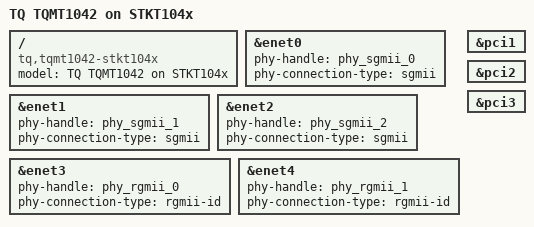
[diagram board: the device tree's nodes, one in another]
// SPDX-License-Identifier: GPL-2.0-or-later
/*
 * TQMT1042 on STKT104x with serdes configuration 0x86 Device Tree Source
 *
 * Copyright (c) 2016-2023 TQ-Systems GmbH <license@tq-group.com>, D-82229 Seefeld, Germany.
 * Copyright 2014 Freescale Semiconductor Inc.
 * Author: Stefan Lange, Max Merchel, Gregor Herburger
 *
 */

#include "t104xsi-pre.dtsi"

#include "tqmt10xx.dtsi"
#include "stkt104x.dtsi"

/ {
	model = "TQ TQMT1042 on STKT104x";
	compatible = "tq,tqmt1042-stkt104x", "tq,tqmt1042";
};

#include "t1042si-post.dtsi"

&enet0 {
	phy-handle = <&phy_sgmii_0>;
	phy-connection-type = "sgmii";
};

&enet1 {
	phy-handle = <&phy_sgmii_1>;
	phy-connection-type = "sgmii";
};

&enet2 {
	phy-handle = <&phy_sgmii_2>;
	phy-connection-type = "sgmii";
};

&enet3 {
	phy-handle = <&phy_rgmii_0>;
	phy-connection-type = "rgmii-id";
};

&enet4 {
	phy-handle = <&phy_rgmii_1>;
	phy-connection-type = "rgmii-id";
};

&pci1 {
	status = "okay";
};

&pci2 {
	status = "okay";
};

&pci3 {
	status = "okay";
};
